AUTOSAR XML (schema 4-0-3)
package /ComponentTypes
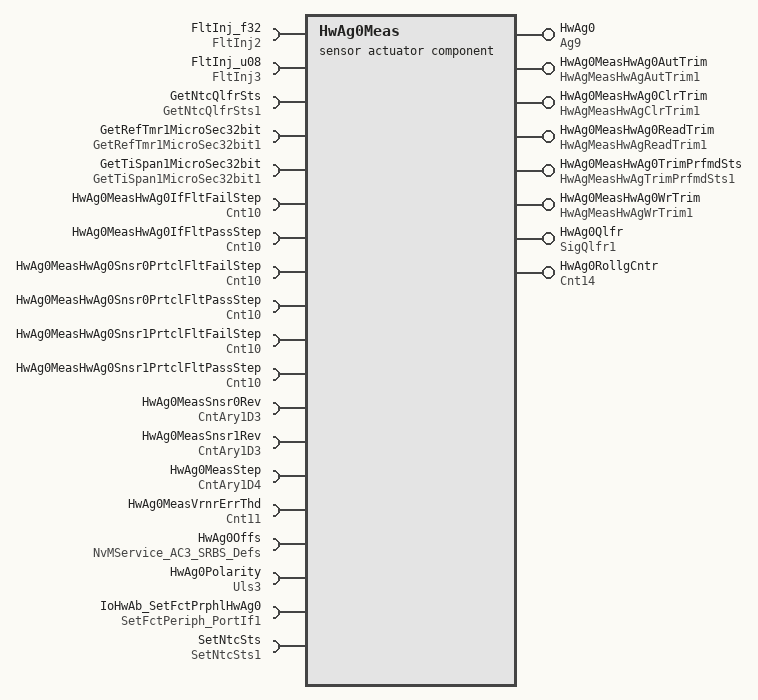
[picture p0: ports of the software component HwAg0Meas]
  sensor actuator sw component type HwAg0Meas
    8 x provide port:
      HwAg0: nonqueued-sender-com-spec{data-element=Val, init-value=0}, provided-interface=Ag9
      HwAg0MeasHwAg0AutTrim: server-com-spec{operation=Oper, queue-length=1}, provided-interface=HwAgMeasHwAgAutTrim1
      HwAg0MeasHwAg0ClrTrim: server-com-spec{operation=Oper, queue-length=1}, provided-interface=HwAgMeasHwAgClrTrim1
      HwAg0MeasHwAg0ReadTrim: server-com-spec{operation=Oper, queue-length=1}, provided-interface=HwAgMeasHwAgReadTrim1
      HwAg0MeasHwAg0TrimPrfmdSts: server-com-spec{operation=Oper, queue-length=1}, provided-interface=HwAgMeasHwAgTrimPrfmdSts1
      HwAg0MeasHwAg0WrTrim: server-com-spec{operation=Oper, queue-length=1}, provided-interface=HwAgMeasHwAgWrTrim1
      HwAg0Qlfr: nonqueued-sender-com-spec{data-element=Val, init-value=0}, provided-interface=SigQlfr1
      HwAg0RollgCntr: nonqueued-sender-com-spec{data-element=Val, init-value=0}, provided-interface=Cnt14
    19 x require port:
      FltInj_f32: required-interface=FltInj2
      FltInj_u08: required-interface=FltInj3
      GetNtcQlfrSts: required-interface=GetNtcQlfrSts1
      GetRefTmr1MicroSec32bit: required-interface=GetRefTmr1MicroSec32bit1
      GetTiSpan1MicroSec32bit: required-interface=GetTiSpan1MicroSec32bit1
      HwAg0MeasHwAg0IfFltFailStep: parameter-require-com-spec{init-value=2521, parameter=Val}, required-interface=Cnt10
      HwAg0MeasHwAg0IfFltPassStep: parameter-require-com-spec{init-value=1000, parameter=Val}, required-interface=Cnt10
      HwAg0MeasHwAg0Snsr0PrtclFltFailStep: parameter-require-com-spec{init-value=2521, parameter=Val}, required-interface=Cnt10
      HwAg0MeasHwAg0Snsr0PrtclFltPassStep: parameter-require-com-spec{init-value=1000, parameter=Val}, required-interface=Cnt10
      HwAg0MeasHwAg0Snsr1PrtclFltFailStep: parameter-require-com-spec{init-value=2521, parameter=Val}, required-interface=Cnt10
      HwAg0MeasHwAg0Snsr1PrtclFltPassStep: parameter-require-com-spec{init-value=1000, parameter=Val}, required-interface=Cnt10
      HwAg0MeasSnsr0Rev: parameter-require-com-spec{init-value=[0, 1, 1, 2, 2, 3, 3, 4, 4, 5, 5, 6, 6, 7, 7, 8, 8, 9, 9, 10, 10, 0], parameter=Ary1D}, required-interface=CntAry1D3
      HwAg0MeasSnsr1Rev: parameter-require-com-spec{init-value=[0, 0, 1, 1, 2, 2, 3, 3, 4, 4, 5, 5, 6, 6, 7, 7, 8, 8, 9, 9, 10, 10], parameter=Ary1D}, required-interface=CntAry1D3
      HwAg0MeasStep: parameter-require-com-spec{init-value=[0, -360, 36, -324, 72, -288, 108, -252, 144, -216, 180, -180, 216, -144, 252, -108, 288, -72, 324, -36, 360, -396], parameter=Ary1D}, required-interface=CntAry1D4
      HwAg0MeasVrnrErrThd: parameter-require-com-spec{init-value=8, parameter=Val}, required-interface=Cnt11
      HwAg0Offs: required-interface=NvMService_AC3_SRBS_Defs
      HwAg0Polarity: nonqueued-receiver-com-spec{data-element=Val, filter=data-filter-type=ALWAYS, init-value=1}, required-interface=Uls3
      IoHwAb_SetFctPrphlHwAg0: required-interface=SetFctPeriph_PortIf1
      SetNtcSts: required-interface=SetNtcSts1
    behavior HwAg0Meas_InternalBehavior: data-type-mapping=Nexteer
      ar-typed-per-instance-memorys:
        29 x data, all with sw-calibration-access=READ-ONLY:
          dHwAg0MeasSnsr0Abs: type=Cnt34
          dHwAg0MeasSnsr0CS: type=uint32
          dHwAg0MeasSnsr0FRXD: type=uint32
          dHwAg0MeasSnsr0Rel: type=Cnt32
          dHwAg0MeasSnsr1Abs: type=Cnt34
          dHwAg0MeasSnsr1CS: type=uint32
          dHwAg0MeasSnsr1FRXD: type=uint32
          dHwAg0MeasSnsr1Rel: type=Cnt32
          HwAg0InitStepSeqNrCmpl: type=Logl1
          HwAg0Offs: type=HwAgOffsRecAppl1
          HwAg0PrevHwAg0: type=Ag19
          HwAg0PrevRollCnt: type=Cnt19
          HwAg0PrevStepSeqNr: type=Cnt33
          HwAg0RawDataAvlStrtTi: type=uint32
          HwAg0Snsr0ComStsErrCntr: type=uint8
          HwAg0Snsr0IdErrCntr: type=uint8
          HwAg0Snsr0IntSnsrErrCntr: type=uint8
          HwAg0Snsr0NoMsgErrCntr: type=uint8
          HwAg0Snsr1ComStsErrCntr: type=uint8
          HwAg0Snsr1IdErrCntr: type=uint8
          HwAg0Snsr1IntSnsrErrCntr: type=uint8
          HwAg0Snsr1NoMsgErrCntr: type=uint8
          HwAg0SnsrTrigNr: type=uint8
          PrevHwAg0: type=float32
          PrevHwAg0Qlfr: type=SigQlfr1
          PrevHwAg0Snsr0Raw: type=uint16
          PrevHwAg0Snsr0TestOk: type=uint8
          PrevHwAg0Snsr1Raw: type=uint16
          PrevHwAg0Snsr1TestOk: type=uint8
      5 x operation invoked event:
        OIT_HwAg0MeasHwAg0AutTrim_Oper_HwAg0MeasHwAg0AutTrim_Oper: start-on-event=HwAg0MeasHwAg0AutTrim_Oper, operation=HwAg0MeasHwAg0AutTrim.Oper
        OIT_HwAg0MeasHwAg0ClrTrim_Oper_1_HwAg0MeasHwAg0ClrTrim_Oper: start-on-event=HwAg0MeasHwAg0ClrTrim_Oper, operation=HwAg0MeasHwAg0ClrTrim.Oper
        OIT_HwAg0MeasHwAg0ReadTrim_Oper_HwAg0MeasHwAg0ReadTrim_Oper: start-on-event=HwAg0MeasHwAg0ReadTrim_Oper, operation=HwAg0MeasHwAg0ReadTrim.Oper
        OIT_HwAg0MeasHwAg0TrimPrfmdSts_Oper_HwAg0MeasHwAg0TrimPrfmdSts_Oper: start-on-event=HwAg0MeasHwAg0TrimPrfmdSts_Oper, operation=HwAg0MeasHwAg0TrimPrfmdSts.Oper
        OIT_HwAg0MeasHwAg0WrTrim_Oper_1_HwAg0MeasHwAg0WrTrim_Oper: start-on-event=HwAg0MeasHwAg0WrTrim_Oper, operation=HwAg0MeasHwAg0WrTrim.Oper
      6 x timing event:
        HwAg0Meas_InitEvent: start-on-event=HwAg0MeasInit1, period=0
        TMT_HwAg0MeasPer{1..4}: start-on-event=HwAg0MeasPer{1..4}, period=0.002
        TMT_HwAg0MeasPer5: start-on-event=HwAg0MeasPer5, period=0.1
      explicit-inter-runnable-variables:
        4 x data, all with init-value=0:
          HwAg0Snsr0Raw: type=Cnt31
          HwAg0Snsr0TestOk: type=Cnt13
          HwAg0Snsr1Raw: type=Cnt31
          HwAg0Snsr1TestOk: type=Cnt13
      11 x runnable:
        HwAg0MeasHwAg0AutTrim_Oper
          sync call SC_HwAg0Offs_SetRamBlockStatus: operation=HwAg0Offs.SetRamBlockStatus, timeout=0
        HwAg0MeasHwAg0ClrTrim_Oper
          sync call SC_HwAg0Offs_SetRamBlockStatus: operation=HwAg0Offs.SetRamBlockStatus, timeout=0
        HwAg0MeasHwAg0ReadTrim_Oper
        HwAg0MeasHwAg0TrimPrfmdSts_Oper
        HwAg0MeasHwAg0WrTrim_Oper
          sync call SC_HwAg0Offs_SetRamBlockStatus: operation=HwAg0Offs.SetRamBlockStatus, timeout=0
        HwAg0MeasInit1
          sync call SC_GetRefTmr1MicroSec32bit_Oper: operation=GetRefTmr1MicroSec32bit.Oper, timeout=0
          sync call SC_GetTiSpan1MicroSec32bit_Oper: operation=GetTiSpan1MicroSec32bit.Oper, timeout=0
          sync call SC_IoHwAb_SetFctPrphlHwAg0_Oper: operation=IoHwAb_SetFctPrphlHwAg0.Oper, timeout=0
        HwAg0MeasPer1
          sync call SC_GetRefTmr1MicroSec32bit_Oper: operation=GetRefTmr1MicroSec32bit.Oper, timeout=0
          sync call SC_GetTiSpan1MicroSec32bit_Oper: operation=GetTiSpan1MicroSec32bit.Oper, timeout=0
        HwAg0MeasPer2
          4 x sync call, all with timeout=0:
            SC_FltInj_u08_Oper: operation=FltInj_u08.Oper
            SC_GetRefTmr1MicroSec32bit_Oper: operation=GetRefTmr1MicroSec32bit.Oper
            SC_GetTiSpan1MicroSec32bit_Oper: operation=GetTiSpan1MicroSec32bit.Oper
            SC_SetNtcSts_Oper: operation=SetNtcSts.Oper
          written-local-variables:
            access WRITE_HwAg0Snsr0Raw: accessed-variable=HwAg0Snsr0Raw
            access WRITE_HwAg0Snsr0TestOk: accessed-variable=HwAg0Snsr0TestOk
        HwAg0MeasPer3
          sync call SC_FltInj_u08_Oper: operation=FltInj_u08.Oper, timeout=0
          sync call SC_GetTiSpan1MicroSec32bit_Oper: operation=GetTiSpan1MicroSec32bit.Oper, timeout=0
          sync call SC_SetNtcSts_Oper: operation=SetNtcSts.Oper, timeout=0
          written-local-variables:
            4 x access:
              WRITE_HwAg0Snsr0Raw: accessed-variable=HwAg0Snsr0Raw
              WRITE_HwAg0Snsr0TestOk: accessed-variable=HwAg0Snsr0TestOk
              WRITE_HwAg0Snsr1Raw: accessed-variable=HwAg0Snsr1Raw
              WRITE_HwAg0Snsr1TestOk: accessed-variable=HwAg0Snsr1TestOk
        HwAg0MeasPer4
          data-receive-point-by-arguments:
            access REC_HwAg0Polarity_Val: accessed-variable=HwAg0Polarity.Val
          data-send-points:
            access SEND_HwAg0_Val: accessed-variable=HwAg0.Val
            access SEND_HwAg0Qlfr_Val: accessed-variable=HwAg0Qlfr.Val
            access SEND_HwAg0RollgCntr_Val: accessed-variable=HwAg0RollgCntr.Val
          read-local-variables:
            4 x access:
              READ_HwAg0Snsr0Raw: accessed-variable=HwAg0Snsr0Raw
              READ_HwAg0Snsr0TestOk: accessed-variable=HwAg0Snsr0TestOk
              READ_HwAg0Snsr1Raw: accessed-variable=HwAg0Snsr1Raw
              READ_HwAg0Snsr1TestOk: accessed-variable=HwAg0Snsr1TestOk
          5 x sync call, all with timeout=0:
            SC_FltInj_f32_Oper: operation=FltInj_f32.Oper
            SC_GetNtcQlfrSts_Oper: operation=GetNtcQlfrSts.Oper
            SC_GetRefTmr1MicroSec32bit_Oper: operation=GetRefTmr1MicroSec32bit.Oper
            SC_GetTiSpan1MicroSec32bit_Oper: operation=GetTiSpan1MicroSec32bit.Oper
            SC_SetNtcSts_Oper: operation=SetNtcSts.Oper
          written-local-variables:
            access WRITE_HwAg0Snsr1Raw: accessed-variable=HwAg0Snsr1Raw
            access WRITE_HwAg0Snsr1TestOk: accessed-variable=HwAg0Snsr1TestOk
        HwAg0MeasPer5
          data-receive-point-by-arguments:
            access REC_HwAg0Polarity_Val: accessed-variable=HwAg0Polarity.Val
          data-send-points:
            access SEND_HwAg0_Val: accessed-variable=HwAg0.Val
            access SEND_HwAg0Qlfr_Val: accessed-variable=HwAg0Qlfr.Val
            access SEND_HwAg0RollgCntr_Val: accessed-variable=HwAg0RollgCntr.Val
          read-local-variables:
            4 x access:
              READ_HwAg0Snsr0Raw: accessed-variable=HwAg0Snsr0Raw
              READ_HwAg0Snsr0TestOk: accessed-variable=HwAg0Snsr0TestOk
              READ_HwAg0Snsr1Raw: accessed-variable=HwAg0Snsr1Raw
              READ_HwAg0Snsr1TestOk: accessed-variable=HwAg0Snsr1TestOk
          sync call SC_FltInj_f32_Oper: operation=FltInj_f32.Oper, timeout=0
          sync call SC_GetNtcQlfrSts_Oper: operation=GetNtcQlfrSts.Oper, timeout=0
          sync call SC_SetNtcSts_Oper: operation=SetNtcSts.Oper, timeout=0
      swc service dependency NvmHwAg0Offs: assigned-datas=[{role=ramBlock, used-data-element=HwAg0Offs}, {role=defaultValue, used-parameter-element=HwAg0OffsDft}]
        assigned-ports:
          port-prototype=HwAg0Offs, role=NvMService_AC3_SRBS_Defs
          port-prototype=HwAg0Offs, role=NvMService_AC3_SRBS_Defs
        service-needs:
          nv block needs NvmHwAg0Offs: n-data-sets=0, readonly=false, reliability=ERROR-DETECTION, resistant-to-changed-sw=true, restore-at-start=true, store-at-shutdown=true, write-only-once=false, writing-frequency=0, writing-priority=LOW
      shared-parameters:
        parameter data prototype HwAg0OffsDft: sw-calibration-access=READ-WRITE, type=HwAgOffsRecAppl1, init-value=fields=[OffsTrim:0, OffsTrimPrfmdSts:0]
  swc implementation HwAg0Meas_Implementation: behavior=HwAg0Meas_InternalBehavior
    code-descriptors:
      code Default: artifact-descriptors=autosar-engineering-object={short-label=Default, category=SWSRC}
